AUTOSAR XML (schema 4-2-1)
package /RootP_ASWC_M743
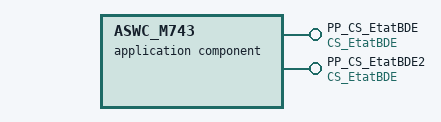
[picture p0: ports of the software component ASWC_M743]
  application sw component type ASWC_M743
    provide port PP_CS_EtatBDE: provided-interface=CS_EtatBDE
    provide port PP_CS_EtatBDE2: provided-interface=CS_EtatBDE
package /RootP_Composition
  composition sw component type Compo_VSM
    component Instance_ASWC_M743: type=ASWC_M743
